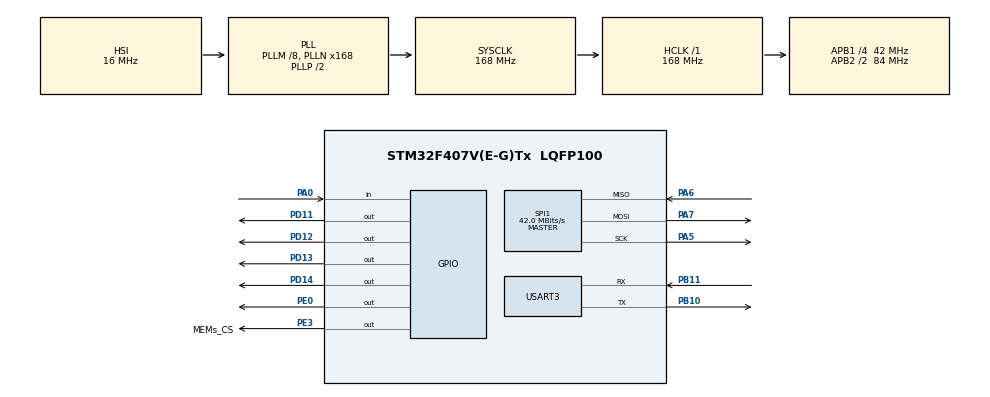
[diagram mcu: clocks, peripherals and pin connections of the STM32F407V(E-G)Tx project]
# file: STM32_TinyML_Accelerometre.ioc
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Mcu.Family=STM32F4
Mcu.Name=STM32F407V(E-G)Tx
Mcu.Package=LQFP100
NVIC.PriorityGroup=NVIC_PRIORITYGROUP_4
PA0-WKUP.Signal=GPIO_Input
PA5.Mode=Full_Duplex_Master
PA5.Signal=SPI1_SCK
PA6.Mode=Full_Duplex_Master
PA6.Signal=SPI1_MISO
PA7.Mode=Full_Duplex_Master
PA7.Signal=SPI1_MOSI
PB10.Mode=Asynchronous
PB10.Signal=USART3_TX
PB11.Mode=Asynchronous
PB11.Signal=USART3_RX
PD11.Signal=GPIO_Output
PD12.Signal=GPIO_Output
PD13.Signal=GPIO_Output
PD14.Signal=GPIO_Output
PE0.Signal=GPIO_Output
PE3.GPIO_Label=MEMs_CS
PE3.Signal=GPIO_Output
ProjectManager.HeapSize=0x800
ProjectManager.StackSize=0x800
ProjectManager.TargetToolchain=STM32CubeIDE
RCC.48MHZClocksFreq_Value=84000000
RCC.AHBFreq_Value=168000000
RCC.APB1CLKDivider=RCC_HCLK_DIV4
RCC.APB1Freq_Value=42000000
RCC.APB1TimFreq_Value=84000000
RCC.APB2CLKDivider=RCC_HCLK_DIV2
RCC.APB2Freq_Value=84000000
RCC.APB2TimFreq_Value=168000000
RCC.CortexFreq_Value=168000000
RCC.HCLKFreq_Value=168000000
RCC.HSE_VALUE=25000000
RCC.HSI_VALUE=16000000
RCC.LSE_VALUE=32768
RCC.PLLM=8
RCC.PLLN=168
RCC.SYSCLKFreq_VALUE=168000000
RCC.SYSCLKSource=RCC_SYSCLKSOURCE_PLLCLK
RCC.VCOOutputFreq_Value=336000000
SPI1.BaudRatePrescaler=SPI_BAUDRATEPRESCALER_2
SPI1.CalculateBaudRate=42.0 MBits/s
SPI1.Direction=SPI_DIRECTION_2LINES
SPI1.Mode=SPI_MODE_MASTER
SPI1.VirtualType=VM_MASTER
STMicroelectronics.X-CUBE-AI.9.1.0.ActivationBufferSizeList=768
STMicroelectronics.X-CUBE-AI.9.1.0.ActivationBuffers=pool0
STMicroelectronics.X-CUBE-AI.9.1.0.ActivationNames=pool0
STMicroelectronics.X-CUBE-AI.9.1.0.ActivationSizes=AI_MODEL_DATA_ACTIVATION_1_SIZE
STMicroelectronics.X-CUBE-AI.9.1.0.HeapSize=0x800
STMicroelectronics.X-CUBE-AI.9.1.0.InternalRamActivationBufferMaxSize=AI_MODEL_DATA_ACTIVATIONS_SIZE
STMicroelectronics.X-CUBE-AI.9.1.0.LatestDirectoryUsed-87cb632043c03ec0848139383c4361631e4bc9c341821ce8527a442e798a6082=/home/skander/Bureau/model-created_nsb
STMicroelectronics.X-CUBE-AI.9.1.0.MaximumNumberOfInputLayer=1
STMicroelectronics.X-CUBE-AI.9.1.0.MaximumNumberOfOutputLayer=1
STMicroelectronics.X-CUBE-AI.9.1.0.MaximumSizeOfInputLayer=1
STMicroelectronics.X-CUBE-AI.9.1.0.MaximumSizeOfOutputLayer=1
STMicroelectronics.X-CUBE-AI.9.1.0.ModelActualCompression-87cb632043c03ec0848139383c4361631e4bc9c341821ce8527a442e798a6082=0.0
STMicroelectronics.X-CUBE-AI.9.1.0.ModelCompression-87cb632043c03ec0848139383c4361631e4bc9c341821ce8527a442e798a6082=None
STMicroelectronics.X-CUBE-AI.9.1.0.ModelFlashOccupation-87cb632043c03ec0848139383c4361631e4bc9c341821ce8527a442e798a6082=36372
STMicroelectronics.X-CUBE-AI.9.1.0.ModelHashList=87cb632043c03ec0848139383c4361631e4bc9c341821ce8527a442e798a6082
STMicroelectronics.X-CUBE-AI.9.1.0.ModelKind-87cb632043c03ec0848139383c4361631e4bc9c341821ce8527a442e798a6082=TFLITE
STMicroelectronics.X-CUBE-AI.9.1.0.ModelMacc-87cb632043c03ec0848139383c4361631e4bc9c341821ce8527a442e798a6082=9360
STMicroelectronics.X-CUBE-AI.9.1.0.ModelName-87cb632043c03ec0848139383c4361631e4bc9c341821ce8527a442e798a6082=model
STMicroelectronics.X-CUBE-AI.9.1.0.ModelNameList=model
STMicroelectronics.X-CUBE-AI.9.1.0.ModelRamOccupation-87cb632043c03ec0848139383c4361631e4bc9c341821ce8527a442e798a6082=768
STMicroelectronics.X-CUBE-AI.9.1.0.ModelStructureFile-87cb632043c03ec0848139383c4361631e4bc9c341821ce8527a442e798a6082=/home/skander/Bureau/model-created_nsb/dnn_model.tflite
STMicroelectronics.X-CUBE-AI.9.1.0.ModelType-87cb632043c03ec0848139383c4361631e4bc9c341821ce8527a442e798a6082=STM32Cube.AI MCU runtime
STMicroelectronics.X-CUBE-AI.9.1.0.ReadyForCodeGeneration=true
STMicroelectronics.X-CUBE-AI.9.1.0.StackSize=0x800
STMicroelectronics.X-CUBE-AI.9.1.0.WorkingBufferStartAddrList=0xFFFFFFFF
STMicroelectronics.X-CUBE-AI.9.1.0.XAaCUBEAaAICcArtificialOoIntelligenceJjCore=true
STMicroelectronics.X-CUBE-AI.9.1.0.copyWeightToRam=false
STMicroelectronics.X-CUBE-AI.9.1.0.copyWeightToRam-87cb632043c03ec0848139383c4361631e4bc9c341821ce8527a442e798a6082=false
STMicroelectronics.X-CUBE-AI.9.1.0.customLayerConfigEnabled=false
STMicroelectronics.X-CUBE-AI.9.1.0.customLayerConfigEnabled-87cb632043c03ec0848139383c4361631e4bc9c341821ce8527a442e798a6082=false
STMicroelectronics.X-CUBE-AI.9.1.0.noOnnxIoTranspose=false
STMicroelectronics.X-CUBE-AI.9.1.0.noOnnxIoTranspose-87cb632043c03ec0848139383c4361631e4bc9c341821ce8527a442e798a6082=false
STMicroelectronics.X-CUBE-AI.9.1.0.outputDirectory=/home/skander/.stm32cubemx/sinemod_output
STMicroelectronics.X-CUBE-AI.9.1.0.useInputAllocation=true
STMicroelectronics.X-CUBE-AI.9.1.0.useInputAllocation-87cb632043c03ec0848139383c4361631e4bc9c341821ce8527a442e798a6082=true
STMicroelectronics.X-CUBE-AI.9.1.0.useOutputAllocation=true
STMicroelectronics.X-CUBE-AI.9.1.0.useOutputAllocation-87cb632043c03ec0848139383c4361631e4bc9c341821ce8527a442e798a6082=true
TIM3.Prescaler=1
USART3.VirtualMode=VM_ASYNC
VP_STMicroelectronics.X-CUBE-AI_VS_ArtificialOoIntelligenceJjXAaCUBEAaAI_9.1.0.Mode=ArtificialOoIntelligenceJjXAaCUBEAaAI
VP_TIM3_VS_ClockSourceINT.Mode=Internal
board=custom

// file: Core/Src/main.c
/* USER CODE BEGIN Header */
/**
  ******************************************************************************
  * @file           : main.c
  * @brief          : Main program body
  ************************************************­******************************
  * @attention
  *
  * Copyright (c) 2024 STMicroelectronics.
  * All rights reserved.
  *
  * This software is licensed under terms that can be found in the LICENSE file
  * in the root directory of this software component.
  * If no LICENSE file comes with this software, it is provided AS-IS.
  *
  ******************************************************************************
  */
/* USER CODE END Header */
#include "main.h"

#include "ai_datatypes_defines.h"
#include "ai_platform.h"

#include "model.h"
#include "model_data.h"

#include "MY_LIS3DSH.h"

#include <stdio.h> // For sprintf

SPI_HandleTypeDef hspi1;

TIM_HandleTypeDef htim3;

UART_HandleTypeDef huart3;

void SystemClock_Config(void);
static void MX_GPIO_Init(void);
static void MX_TIM3_Init(void);
static void MX_USART3_UART_Init(void);
static void MX_SPI1_Init(void);

int main(void)
{

  /* USER CODE BEGIN 1 */
  LIS3DSH_InitTypeDef myAccConfigDef;
  LIS3DSH_DataScaled myData;

  char buf[100];
  int buf_len = 0;
  ai_error ai_err;

  /* Define Activation Buffers */
  AI_ALIGNED(4) ai_u8 activations[AI_MODEL_DATA_ACTIVATIONS_SIZE];
  AI_ALIGNED(4) ai_i8 in_data[AI_MODEL_IN_1_SIZE_BYTES];
  AI_ALIGNED(4) ai_i8 out_data[AI_MODEL_OUT_1_SIZE_BYTES];

  /* Neural Network Handle */
  ai_handle model = AI_HANDLE_NULL;

  /* Input/Output Buffers */
  ai_buffer ai_input[AI_MODEL_IN_NUM];
  ai_buffer* temp = ai_model_inputs_get(AI_HANDLE_NULL, NULL);

  for (int i = 0; i < AI_MODEL_IN_NUM; i++) {
      ai_input[i] = temp[i];
  }

  ai_buffer ai_output[AI_MODEL_OUT_NUM];
  ai_buffer* temp2 = ai_model_outputs_get(AI_HANDLE_NULL, NULL);
  for (int i = 0; i < AI_MODEL_OUT_NUM; i++) {
      ai_output[i] = temp2[i];
  }

  // Set working memory and get weights/biases from model
  ai_network_params ai_params = {
      AI_MODEL_DATA_WEIGHTS(ai_model_data_weights_get()),
      AI_MODEL_DATA_ACTIVATIONS(activations)
  };

  // Set pointers wrapper structs to our data buffers
  ai_input[0].data = AI_HANDLE_PTR(in_data);
  ai_output[0].data = AI_HANDLE_PTR(out_data);

  /* USER CODE END 1 */

  /* MCU Configuration--------------------------------------------------------*/

  /* Reset of all peripherals, Initializes the Flash interface and the Systick. */
  HAL_Init();

  /* Configure the system clock */
  SystemClock_Config();

  /* Initialize all configured peripherals */
  MX_GPIO_Init();
  MX_TIM3_Init();
  MX_USART3_UART_Init();
  MX_SPI1_Init();

  /* USER CODE BEGIN 2 */

	myAccConfigDef.dataRate = LIS3DSH_DATARATE_25;
	myAccConfigDef.fullScale = LIS3DSH_FULLSCALE_4;
	myAccConfigDef.antiAliasingBW = LIS3DSH_FILTER_BW_50;
	myAccConfigDef.enableAxes = LIS3DSH_XYZ_ENABLE;
	myAccConfigDef.interruptEnable = false;
	LIS3DSH_Init(&hspi1, &myAccConfigDef);

	LIS3DSH_X_calibrate(-984.0, 1030.0);
	LIS3DSH_Y_calibrate(-963.0, 1020.0);
	LIS3DSH_Z_calibrate(-940.0, 1036.0);

  buf_len = sprintf(buf, "\r\n\r\nSTM32 X-Cube-AI test\r\n");
  HAL_UART_Transmit(&huart3, (uint8_t *)buf, buf_len, 100);

  // Create instance of neural network
  ai_err = ai_model_create(&model, AI_MODEL_DATA_CONFIG);
  if (ai_err.type != AI_ERROR_NONE)
  {
      buf_len = sprintf(buf, "Error: could not create NN instance\r\n");
      HAL_UART_Transmit(&huart3, (uint8_t *)buf, buf_len, 100);
      while (1);
  }

  // Initialize neural network
  if (!ai_model_init(model, &ai_params))
  {
      buf_len = sprintf(buf, "Error: could not initialize NN\r\n");
      HAL_UART_Transmit(&huart3, (uint8_t *)buf, buf_len, 100);
      while (1);
  }

  /* USER CODE END 2 */

  /* Infinite loop */
  while (1)
  {
	if (LIS3DSH_PollDRDY(1000) == true)
	{
	/* Get accelerometer data */
    myData = LIS3DSH_GetDataScaled();

    // Log accelerometer data
    buf_len = sprintf(buf, "Accel: x=%.2f, y=%.2f, z=%.2f\r\n", myData.x, myData.y, myData.z);
    HAL_UART_Transmit(&huart3, (uint8_t *)buf, buf_len, 100);

    // Map accelerometer data to input buffer
    ((ai_float*)in_data)[0] = myData.x;
    ((ai_float*)in_data)[1] = myData.y;
    ((ai_float*)in_data)[2] = myData.z;

    // Run inference
    if (ai_model_run(model, &ai_input[0], &ai_output[0]) != 1) {
      buf_len = sprintf(buf, "Error: could not run inference\r\n");
      HAL_UART_Transmit(&huart3, (uint8_t *)buf, buf_len, 100);
      continue;
    }

    // Interpret output (find class with highest probability)
    ai_float max_val = 0.0;
    int max_idx = 0;
    for (int i = 0; i < AI_MODEL_OUT_1_SIZE; i++) {
        if (((ai_float*)out_data)[i] > max_val) {
            max_val = ((ai_float*)out_data)[i];
            max_idx = i;
        }
    }

    buf_len = sprintf(buf, "Output Class: %d, Probability: %f\r\n", max_idx, max_val);
    HAL_UART_Transmit(&huart3, (uint8_t *)buf, buf_len, 100);

    // Indicate Tilt Based on Neural Network Output
    switch (max_idx) {
      case 0:
        HAL_GPIO_WritePin(GPIOD, GPIO_PIN_13, GPIO_PIN_SET);  // Blue LED ON
        HAL_GPIO_WritePin(GPIOD, GPIO_PIN_12 | GPIO_PIN_15 | GPIO_PIN_14, GPIO_PIN_RESET);  // Others OFF
        break;
      case 1:
        HAL_GPIO_WritePin(GPIOD, GPIO_PIN_15, GPIO_PIN_SET);  // Orange LED ON
        HAL_GPIO_WritePin(GPIOD, GPIO_PIN_12 | GPIO_PIN_13 | GPIO_PIN_14, GPIO_PIN_RESET);  // Others OFF
        break;
      case 2:
        HAL_GPIO_WritePin(GPIOD, GPIO_PIN_12, GPIO_PIN_SET);  // Green LED ON
        HAL_GPIO_WritePin(GPIOD, GPIO_PIN_13 | GPIO_PIN_14 | GPIO_PIN_15, GPIO_PIN_RESET);  // Others OFF
        break;
      case 3:
        HAL_GPIO_WritePin(GPIOD, GPIO_PIN_14, GPIO_PIN_SET);  // Red LED ON
        HAL_GPIO_WritePin(GPIOD, GPIO_PIN_12 | GPIO_PIN_13 | GPIO_PIN_15, GPIO_PIN_RESET);  // Others OFF
        break;
      //case 4:
        //HAL_GPIO_WritePin(GPIOD, GPIO_PIN_12 | GPIO_PIN_13, GPIO_PIN_SET);  // Example: Turn on two LEDs
        //HAL_GPIO_WritePin(GPIOD, GPIO_PIN_14 | GPIO_PIN_15, GPIO_PIN_RESET);  // Turn off others
        //break;
      default:
        HAL_GPIO_WritePin(GPIOD, GPIO_PIN_12 | GPIO_PIN_13 | GPIO_PIN_14 | GPIO_PIN_15, GPIO_PIN_RESET);  // All OFF
        break;
    }

    HAL_Delay(500); // Delay for simulation
	}
  }
}

void SystemClock_Config(void)
{
  RCC_OscInitTypeDef RCC_OscInitStruct = {0};
  RCC_ClkInitTypeDef RCC_ClkInitStruct = {0};

  /** Configure the main internal regulator output voltage
  */
  __HAL_RCC_PWR_CLK_ENABLE();
  __HAL_PWR_VOLTAGESCALING_CONFIG(PWR_REGULATOR_VOLTAGE_SCALE1);

  /** Initializes the RCC Oscillators according to the specified parameters
  * in the RCC_OscInitTypeDef structure.
  */
  RCC_OscInitStruct.OscillatorType = RCC_OSCILLATORTYPE_HSI;
  RCC_OscInitStruct.HSIState = RCC_HSI_ON;
  RCC_OscInitStruct.HSICalibrationValue = RCC_HSICALIBRATION_DEFAULT;
  RCC_OscInitStruct.PLL.PLLState = RCC_PLL_ON;
  RCC_OscInitStruct.PLL.PLLSource = RCC_PLLSOURCE_HSI;
  RCC_OscInitStruct.PLL.PLLM = 8;
  RCC_OscInitStruct.PLL.PLLN = 168;
  RCC_OscInitStruct.PLL.PLLP = RCC_PLLP_DIV2;
  RCC_OscInitStruct.PLL.PLLQ = 4;
  if (HAL_RCC_OscConfig(&RCC_OscInitStruct) != HAL_OK)
  {
    Error_Handler();
  }

  /** Initializes the CPU, AHB and APB buses clocks
  */
  RCC_ClkInitStruct.ClockType = RCC_CLOCKTYPE_HCLK|RCC_CLOCKTYPE_SYSCLK
                              |RCC_CLOCKTYPE_PCLK1|RCC_CLOCKTYPE_PCLK2;
  RCC_ClkInitStruct.SYSCLKSource = RCC_SYSCLKSOURCE_PLLCLK;
  RCC_ClkInitStruct.AHBCLKDivider = RCC_SYSCLK_DIV1;
  RCC_ClkInitStruct.APB1CLKDivider = RCC_HCLK_DIV4;
  RCC_ClkInitStruct.APB2CLKDivider = RCC_HCLK_DIV2;

  if (HAL_RCC_ClockConfig(&RCC_ClkInitStruct, FLASH_LATENCY_5) != HAL_OK)
  {
    Error_Handler();
  }
}

static void MX_SPI1_Init(void)
{

  /* SPI1 parameter configuration*/
  hspi1.Instance = SPI1;
  hspi1.Init.Mode = SPI_MODE_MASTER;
  hspi1.Init.Direction = SPI_DIRECTION_2LINES;
  hspi1.Init.DataSize = SPI_DATASIZE_8BIT;
  hspi1.Init.CLKPolarity = SPI_POLARITY_LOW;
  hspi1.Init.CLKPhase = SPI_PHASE_1EDGE;
  hspi1.Init.NSS = SPI_NSS_SOFT;
  hspi1.Init.BaudRatePrescaler = SPI_BAUDRATEPRESCALER_2;
  hspi1.Init.FirstBit = SPI_FIRSTBIT_MSB;
  hspi1.Init.TIMode = SPI_TIMODE_DISABLE;
  hspi1.Init.CRCCalculation = SPI_CRCCALCULATION_DISABLE;
  hspi1.Init.CRCPolynomial = 10;
  if (HAL_SPI_Init(&hspi1) != HAL_OK)
  {
    Error_Handler();
  }

}

static void MX_TIM3_Init(void)
{

  TIM_ClockConfigTypeDef sClockSourceConfig = {0};
  TIM_MasterConfigTypeDef sMasterConfig = {0};

  htim3.Instance = TIM3;
  htim3.Init.Prescaler = 1;
  htim3.Init.CounterMode = TIM_COUNTERMODE_UP;
  htim3.Init.Period = 65535;
  htim3.Init.ClockDivision = TIM_CLOCKDIVISION_DIV1;
  htim3.Init.AutoReloadPreload = TIM_AUTORELOAD_PRELOAD_DISABLE;
  if (HAL_TIM_Base_Init(&htim3) != HAL_OK)
  {
    Error_Handler();
  }
  sClockSourceConfig.ClockSource = TIM_CLOCKSOURCE_INTERNAL;
  if (HAL_TIM_ConfigClockSource(&htim3, &sClockSourceConfig) != HAL_OK)
  {
    Error_Handler();
  }
  sMasterConfig.MasterOutputTrigger = TIM_TRGO_RESET;
  sMasterConfig.MasterSlaveMode = TIM_MASTERSLAVEMODE_DISABLE;
  if (HAL_TIMEx_MasterConfigSynchronization(&htim3, &sMasterConfig) != HAL_OK)
  {
    Error_Handler();
  }

}

static void MX_USART3_UART_Init(void)
{

  huart3.Instance = USART3;
  huart3.Init.BaudRate = 115200;
  huart3.Init.WordLength = UART_WORDLENGTH_8B;
  huart3.Init.StopBits = UART_STOPBITS_1;
  huart3.Init.Parity = UART_PARITY_NONE;
  huart3.Init.Mode = UART_MODE_TX_RX;
  huart3.Init.HwFlowCtl = UART_HWCONTROL_NONE;
  huart3.Init.OverSampling = UART_OVERSAMPLING_16;
  if (HAL_UART_Init(&huart3) != HAL_OK)
  {
    Error_Handler();
  }

}

static void MX_GPIO_Init(void)
{
  GPIO_InitTypeDef GPIO_InitStruct = {0};

  /* GPIO Ports Clock Enable */
  __HAL_RCC_GPIOE_CLK_ENABLE();
  __HAL_RCC_GPIOA_CLK_ENABLE();
  __HAL_RCC_GPIOB_CLK_ENABLE();
  __HAL_RCC_GPIOD_CLK_ENABLE();

  /*Configure GPIO pin Output Level */
  HAL_GPIO_WritePin(GPIOE, MEMs_CS_Pin|GPIO_PIN_0, GPIO_PIN_RESET);

  /*Configure GPIO pin Output Level */
  HAL_GPIO_WritePin(GPIOD, GPIO_PIN_11|GPIO_PIN_12|GPIO_PIN_13|GPIO_PIN_14, GPIO_PIN_RESET);

  /*Configure GPIO pins : MEMs_CS_Pin PE0 */
  GPIO_InitStruct.Pin = MEMs_CS_Pin|GPIO_PIN_0;
  GPIO_InitStruct.Mode = GPIO_MODE_OUTPUT_PP;
  GPIO_InitStruct.Pull = GPIO_NOPULL;
  GPIO_InitStruct.Speed = GPIO_SPEED_FREQ_LOW;
  HAL_GPIO_Init(GPIOE, &GPIO_InitStruct);

  /*Configure GPIO pin : PA0 */
  GPIO_InitStruct.Pin = GPIO_PIN_0;
  GPIO_InitStruct.Mode = GPIO_MODE_INPUT;
  GPIO_InitStruct.Pull = GPIO_NOPULL;
  HAL_GPIO_Init(GPIOA, &GPIO_InitStruct);

  /*Configure GPIO pins : PD11 PD12 PD13 PD14 */
  GPIO_InitStruct.Pin = GPIO_PIN_12|GPIO_PIN_13|GPIO_PIN_14|GPIO_PIN_15;
  GPIO_InitStruct.Mode = GPIO_MODE_OUTPUT_PP;
  GPIO_InitStruct.Pull = GPIO_NOPULL;
  GPIO_InitStruct.Speed = GPIO_SPEED_FREQ_LOW;
  HAL_GPIO_Init(GPIOD, &GPIO_InitStruct);

}

void Error_Handler(void)
{
  __disable_irq();
  while (1)
  {
  }
}
